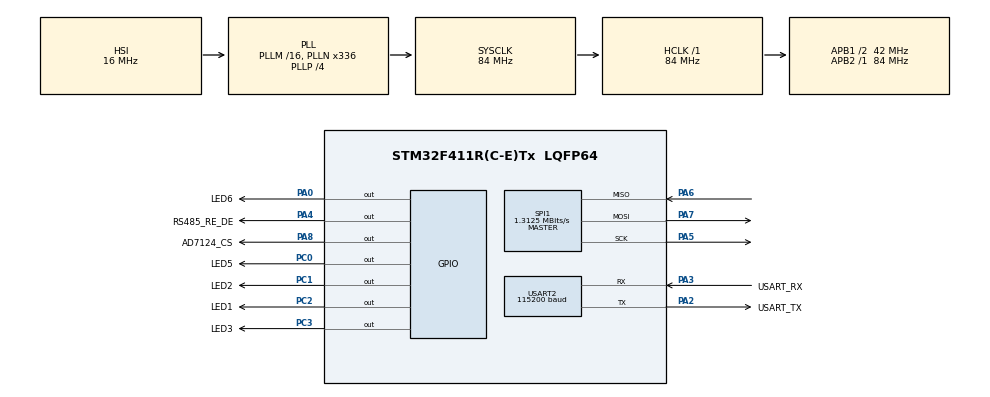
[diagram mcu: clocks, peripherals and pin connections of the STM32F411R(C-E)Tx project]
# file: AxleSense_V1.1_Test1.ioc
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Mcu.Family=STM32F4
Mcu.Name=STM32F411R(C-E)Tx
Mcu.Package=LQFP64
NVIC.PriorityGroup=NVIC_PRIORITYGROUP_0
NVIC.TIM2_IRQn=true\:0\:0\:false\:false\:true\:true\:true\:true
PA0-WKUP.GPIO_Label=LED6
PA0-WKUP.Signal=GPIO_Output
PA13.Mode=Serial_Wire
PA13.Signal=SYS_JTMS-SWDIO
PA14.Mode=Serial_Wire
PA14.Signal=SYS_JTCK-SWCLK
PA2.GPIO_Label=USART_TX
PA2.Mode=Asynchronous
PA2.Signal=USART2_TX
PA3.GPIO_Label=USART_RX
PA3.Mode=Asynchronous
PA3.Signal=USART2_RX
PA4.GPIO_Label=RS485_RE_DE
PA4.Signal=GPIO_Output
PA5.Mode=Full_Duplex_Master
PA5.Signal=SPI1_SCK
PA6.Mode=Full_Duplex_Master
PA6.Signal=SPI1_MISO
PA7.Mode=Full_Duplex_Master
PA7.Signal=SPI1_MOSI
PA8.GPIO_Label=AD7124_CS
PA8.PinState=GPIO_PIN_SET
PA8.Signal=GPIO_Output
PB3.GPIO_Label=SWO
PB3.Signal=SYS_JTDO-SWO
PC0.GPIO_Label=LED5
PC0.Signal=GPIO_Output
PC1.GPIO_Label=LED2
PC1.Signal=GPIO_Output
PC2.GPIO_Label=LED1
PC2.Signal=GPIO_Output
PC3.GPIO_Label=LED3
PC3.Signal=GPIO_Output
ProjectManager.HeapSize=0x200
ProjectManager.StackSize=0x400
ProjectManager.TargetToolchain=STM32CubeIDE
RCC.48MHZClocksFreq_Value=84000000
RCC.AHBFreq_Value=84000000
RCC.APB1CLKDivider=RCC_HCLK_DIV2
RCC.APB1Freq_Value=42000000
RCC.APB1TimFreq_Value=84000000
RCC.APB2Freq_Value=84000000
RCC.APB2TimFreq_Value=84000000
RCC.CortexFreq_Value=84000000
RCC.FLatency-AdvancedSettings=FLASH_LATENCY_2
RCC.HCLKFreq_Value=84000000
RCC.HSE_VALUE=8000000
RCC.HSI_VALUE=16000000
RCC.PLLN=336
RCC.PLLP=RCC_PLLP_DIV4
RCC.SYSCLKFreq_VALUE=84000000
RCC.SYSCLKSource=RCC_SYSCLKSOURCE_PLLCLK
RCC.VCOOutputFreq_Value=336000000
SPI1.BaudRatePrescaler=SPI_BAUDRATEPRESCALER_64
SPI1.CLKPhase=SPI_PHASE_2EDGE
SPI1.CLKPolarity=SPI_POLARITY_HIGH
SPI1.CalculateBaudRate=1.3125 MBits/s
SPI1.Direction=SPI_DIRECTION_2LINES
SPI1.Mode=SPI_MODE_MASTER
SPI1.VirtualType=VM_MASTER
TIM2.CounterMode=TIM_COUNTERMODE_UP
TIM2.Period=4294967295
TIM2.Prescaler=83
USART2.BaudRate=115200
USART2.VirtualMode=VM_ASYNC
VP_TIM2_VS_ClockSourceINT.Mode=Internal
board=NUCLEO-F411RE

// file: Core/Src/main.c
/* USER CODE BEGIN Header */
/**
  ******************************************************************************
  * @file           : main.c
  * @brief          : Main program body
  ******************************************************************************
  * @attention
  *
  * Copyright (c) 2026 STMicroelectronics.
  * All rights reserved.
  *
  * This software is licensed under terms that can be found in the LICENSE file
  * in the root directory of this software component.
  * If no LICENSE file comes with this software, it is provided AS-IS.
  *
  ******************************************************************************
  */
/* USER CODE END Header */
#include "main.h"

/* USER CODE BEGIN Includes */
#include "app.h"
/* USER CODE END Includes */

SPI_HandleTypeDef hspi1;

TIM_HandleTypeDef htim2;

UART_HandleTypeDef huart2;

void SystemClock_Config(void);
static void MX_GPIO_Init(void);
static void MX_USART2_UART_Init(void);
static void MX_SPI1_Init(void);
static void MX_TIM2_Init(void);

int main(void)
{

  /* MCU Configuration--------------------------------------------------------*/

  /* Reset of all peripherals, Initializes the Flash interface and the Systick. */
  HAL_Init();

  /* Configure the system clock */
  SystemClock_Config();

  /* Initialize all configured peripherals */
  MX_GPIO_Init();
  MX_USART2_UART_Init();
  MX_SPI1_Init();
  MX_TIM2_Init();
  /* USER CODE BEGIN 2 */
  App_Init(&hspi1, &huart2);

  /* USER CODE END 2 */

  /* Infinite loop */
  /* USER CODE BEGIN WHILE */
while (1)
{
    App_Process();
}
    /* USER CODE END WHILE */

}

void SystemClock_Config(void)
{
  RCC_OscInitTypeDef RCC_OscInitStruct = {0};
  RCC_ClkInitTypeDef RCC_ClkInitStruct = {0};

  /** Configure the main internal regulator output voltage
  */
  __HAL_RCC_PWR_CLK_ENABLE();
  __HAL_PWR_VOLTAGESCALING_CONFIG(PWR_REGULATOR_VOLTAGE_SCALE1);

  /** Initializes the RCC Oscillators according to the specified parameters
  * in the RCC_OscInitTypeDef structure.
  */
  RCC_OscInitStruct.OscillatorType = RCC_OSCILLATORTYPE_HSI;
  RCC_OscInitStruct.HSIState = RCC_HSI_ON;
  RCC_OscInitStruct.HSICalibrationValue = RCC_HSICALIBRATION_DEFAULT;
  RCC_OscInitStruct.PLL.PLLState = RCC_PLL_ON;
  RCC_OscInitStruct.PLL.PLLSource = RCC_PLLSOURCE_HSI;
  RCC_OscInitStruct.PLL.PLLM = 16;
  RCC_OscInitStruct.PLL.PLLN = 336;
  RCC_OscInitStruct.PLL.PLLP = RCC_PLLP_DIV4;
  RCC_OscInitStruct.PLL.PLLQ = 4;
  if (HAL_RCC_OscConfig(&RCC_OscInitStruct) != HAL_OK)
  {
    Error_Handler();
  }

  /** Initializes the CPU, AHB and APB buses clocks
  */
  RCC_ClkInitStruct.ClockType = RCC_CLOCKTYPE_HCLK|RCC_CLOCKTYPE_SYSCLK
                              |RCC_CLOCKTYPE_PCLK1|RCC_CLOCKTYPE_PCLK2;
  RCC_ClkInitStruct.SYSCLKSource = RCC_SYSCLKSOURCE_PLLCLK;
  RCC_ClkInitStruct.AHBCLKDivider = RCC_SYSCLK_DIV1;
  RCC_ClkInitStruct.APB1CLKDivider = RCC_HCLK_DIV2;
  RCC_ClkInitStruct.APB2CLKDivider = RCC_HCLK_DIV1;

  if (HAL_RCC_ClockConfig(&RCC_ClkInitStruct, FLASH_LATENCY_2) != HAL_OK)
  {
    Error_Handler();
  }
}

static void MX_SPI1_Init(void)
{

  /* SPI1 parameter configuration*/
  hspi1.Instance = SPI1;
  hspi1.Init.Mode = SPI_MODE_MASTER;
  hspi1.Init.Direction = SPI_DIRECTION_2LINES;
  hspi1.Init.DataSize = SPI_DATASIZE_8BIT;
  hspi1.Init.CLKPolarity = SPI_POLARITY_HIGH;
  hspi1.Init.CLKPhase = SPI_PHASE_2EDGE;
  hspi1.Init.NSS = SPI_NSS_SOFT;
  hspi1.Init.BaudRatePrescaler = SPI_BAUDRATEPRESCALER_64;
  hspi1.Init.FirstBit = SPI_FIRSTBIT_MSB;
  hspi1.Init.TIMode = SPI_TIMODE_DISABLE;
  hspi1.Init.CRCCalculation = SPI_CRCCALCULATION_DISABLE;
  hspi1.Init.CRCPolynomial = 10;
  if (HAL_SPI_Init(&hspi1) != HAL_OK)
  {
    Error_Handler();
  }

}

static void MX_USART2_UART_Init(void)
{

  huart2.Instance = USART2;
  huart2.Init.BaudRate = 115200;
  huart2.Init.WordLength = UART_WORDLENGTH_8B;
  huart2.Init.StopBits = UART_STOPBITS_1;
  huart2.Init.Parity = UART_PARITY_NONE;
  huart2.Init.Mode = UART_MODE_TX_RX;
  huart2.Init.HwFlowCtl = UART_HWCONTROL_NONE;
  huart2.Init.OverSampling = UART_OVERSAMPLING_16;
  if (HAL_UART_Init(&huart2) != HAL_OK)
  {
    Error_Handler();
  }

}

static void MX_TIM2_Init(void)
{

  TIM_ClockConfigTypeDef sClockSourceConfig = {0};

  htim2.Instance = TIM2;
  htim2.Init.Prescaler = 83;
  htim2.Init.CounterMode = TIM_COUNTERMODE_UP;
  htim2.Init.Period = 0xFFFFFFFF;
  htim2.Init.ClockDivision = TIM_CLOCKDIVISION_DIV1;
  htim2.Init.AutoReloadPreload = TIM_AUTORELOAD_PRELOAD_DISABLE;
  if (HAL_TIM_Base_Init(&htim2) != HAL_OK)
  {
    Error_Handler();
  }
  sClockSourceConfig.ClockSource = TIM_CLOCKSOURCE_INTERNAL;
  if (HAL_TIM_ConfigClockSource(&htim2, &sClockSourceConfig) != HAL_OK)
  {
    Error_Handler();
  }

}

static void MX_GPIO_Init(void)
{
  GPIO_InitTypeDef GPIO_InitStruct = {0};

  /* GPIO Ports Clock Enable */
  __HAL_RCC_GPIOC_CLK_ENABLE();
  __HAL_RCC_GPIOA_CLK_ENABLE();
  __HAL_RCC_GPIOB_CLK_ENABLE();

  /*Configure GPIO pin Output Level */
  HAL_GPIO_WritePin(GPIOC, LED5_Pin|LED2_Pin|LED1_Pin|LED3_Pin, GPIO_PIN_RESET);

  /*Configure GPIO pin Output Level */
  HAL_GPIO_WritePin(GPIOA, LED6_Pin|RS485_RE_DE_Pin, GPIO_PIN_RESET);

  /*Configure GPIO pin Output Level */
  HAL_GPIO_WritePin(AD7124_CS_GPIO_Port, AD7124_CS_Pin, GPIO_PIN_SET);

  /*Configure GPIO pins : LED5_Pin LED2_Pin LED1_Pin LED3_Pin */
  GPIO_InitStruct.Pin = LED5_Pin|LED2_Pin|LED1_Pin|LED3_Pin;
  GPIO_InitStruct.Mode = GPIO_MODE_OUTPUT_PP;
  GPIO_InitStruct.Pull = GPIO_NOPULL;
  GPIO_InitStruct.Speed = GPIO_SPEED_FREQ_LOW;
  HAL_GPIO_Init(GPIOC, &GPIO_InitStruct);

  /*Configure GPIO pins : LED6_Pin RS485_RE_DE_Pin AD7124_CS_Pin */
  GPIO_InitStruct.Pin = LED6_Pin|RS485_RE_DE_Pin|AD7124_CS_Pin;
  GPIO_InitStruct.Mode = GPIO_MODE_OUTPUT_PP;
  GPIO_InitStruct.Pull = GPIO_NOPULL;
  GPIO_InitStruct.Speed = GPIO_SPEED_FREQ_LOW;
  HAL_GPIO_Init(GPIOA, &GPIO_InitStruct);

}

void Error_Handler(void)
{
  __disable_irq();
  while (1)
  {
  }
}
